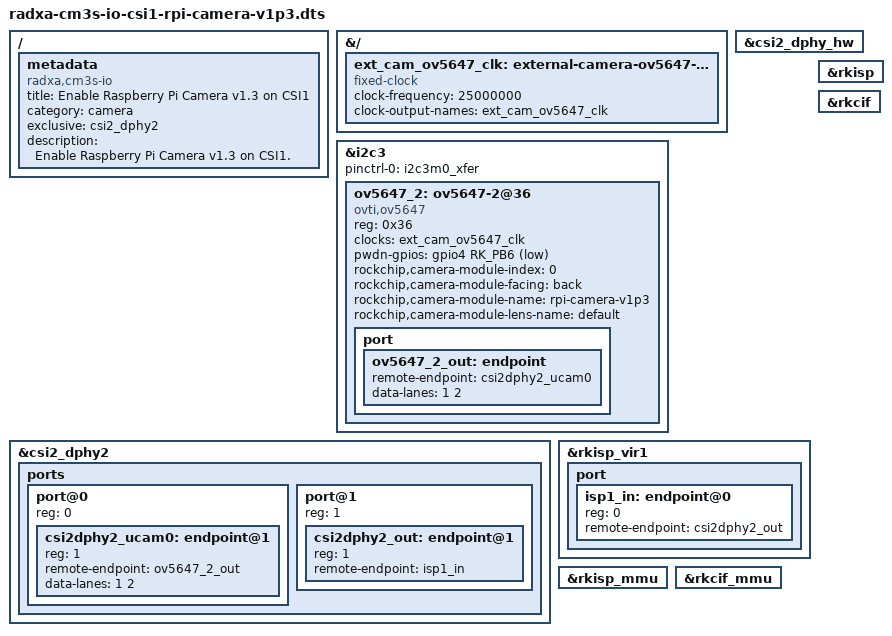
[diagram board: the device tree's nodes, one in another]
/dts-v1/;
/plugin/;

#include <dt-bindings/gpio/gpio.h>
#include <dt-bindings/pinctrl/rockchip.h>

/ {
	metadata {
		title = "Enable Raspberry Pi Camera v1.3 on CSI1";
		compatible = "radxa,cm3s-io", "radxa,radxa-cm3-sodimm-io";
		category = "camera";
		exclusive = "csi2_dphy2";
		description = "Enable Raspberry Pi Camera v1.3 on CSI1.";
	};
};

&{/} {
	ext_cam_ov5647_clk: external-camera-ov5647-clock {
		status = "okay";
		compatible = "fixed-clock";
		clock-frequency = <25000000>;
		clock-output-names = "ext_cam_ov5647_clk";
		#clock-cells = <0>;
	};
};

&i2c3 {
	status = "okay";
	pinctrl-names = "default";
	pinctrl-0 = <&i2c3m0_xfer>;
	#address-cells = <1>;
	#size-cells = <0>;

	ov5647_2: ov5647-2@36 {
		status = "okay";
		compatible = "ovti,ov5647";
		reg = <0x36>;
		clocks = <&ext_cam_ov5647_clk>;
		clock-names = "ext_cam_ov5647_clk";
		pwdn-gpios = <&gpio4 RK_PB6 GPIO_ACTIVE_LOW>;
		rockchip,camera-module-index = <0>;
		rockchip,camera-module-facing = "back";
		rockchip,camera-module-name = "rpi-camera-v1p3";
		rockchip,camera-module-lens-name = "default";

		port {
			ov5647_2_out: endpoint {
				remote-endpoint = <&csi2dphy2_ucam0>;
				data-lanes = <1 2>;
			};
		};
	};
};

&csi2_dphy_hw {
	status = "okay";
};

&csi2_dphy2 {
	status = "okay";

	ports {
		#address-cells = <1>;
		#size-cells = <0>;

		port@0 {
			reg = <0>;
			#address-cells = <1>;
			#size-cells = <0>;

			csi2dphy2_ucam0: endpoint@1 {
				reg = <1>;
				remote-endpoint = <&ov5647_2_out>;
				data-lanes = <1 2>;
			};
		};

		port@1 {
			reg = <1>;
			#address-cells = <1>;
			#size-cells = <0>;

			csi2dphy2_out: endpoint@1 {
				reg = <1>;
				remote-endpoint = <&isp1_in>;
			};
		};
	};
};

&rkisp_vir1 {
	status = "okay";
	#address-cells = <1>;
	#size-cells = <0>;

	port {
		#address-cells = <1>;
		#size-cells = <0>;

		isp1_in: endpoint@0 {
			reg = <0>;
			remote-endpoint = <&csi2dphy2_out>;
		};
	};
};

&rkisp {
	status = "okay";
};

&rkisp_mmu {
	status = "okay";
};

&rkcif_mmu {
	status = "okay";
};

&rkcif {
	status = "okay";
};
